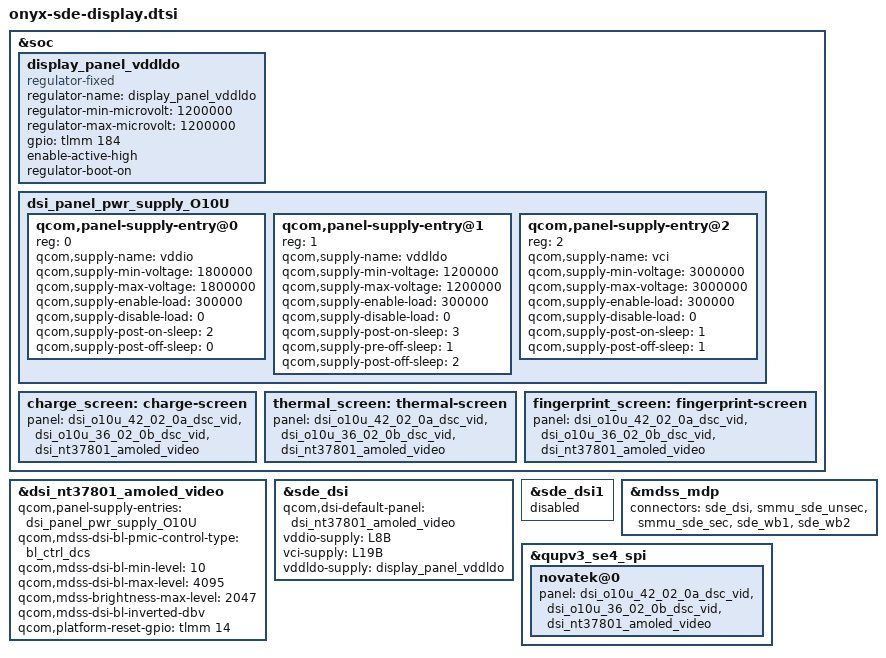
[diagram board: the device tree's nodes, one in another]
#include "tuna-sde-display.dtsi"
#include "dsi-panel-o10u-42-02-0a-dsc-vid.dtsi"
#include "dsi-panel-o10u-36-02-0b-dsc-vid.dtsi"

&soc {
        display_panel_vddldo: display_panel_vddldo {
                compatible = "regulator-fixed";
                regulator-name = "display_panel_vddldo";
                regulator-min-microvolt = <1200000>;
                regulator-max-microvolt = <1200000>;
                gpio = <&tlmm 184 0>;
                enable-active-high;
                regulator-boot-on;
        };

        dsi_panel_pwr_supply_O10U: dsi_panel_pwr_supply_O10U {
                qcom,panel-supply-entry@0 {
                        reg = <0>;
                        qcom,supply-name = "vddio";
                        qcom,supply-min-voltage = <1800000>;
                        qcom,supply-max-voltage = <1800000>;
                        qcom,supply-enable-load = <300000>;
                        qcom,supply-disable-load = <0>;
                        qcom,supply-post-on-sleep = <2>;
                        qcom,supply-post-off-sleep = <0>;
                };
                qcom,panel-supply-entry@1 {
                        reg = <1>;
                        qcom,supply-name = "vddldo";
                        qcom,supply-min-voltage = <1200000>;
                        qcom,supply-max-voltage = <1200000>;
                        qcom,supply-enable-load = <300000>;
                        qcom,supply-disable-load = <0>;
                        qcom,supply-post-on-sleep = <3>;
                        qcom,supply-pre-off-sleep = <1>;
                        qcom,supply-post-off-sleep = <2>;

                };
                qcom,panel-supply-entry@2 {
                        reg = <2>;
                        qcom,supply-name = "vci";
                        qcom,supply-min-voltage = <3000000>;
                        qcom,supply-max-voltage = <3000000>;
                        qcom,supply-enable-load = <300000>;
                        qcom,supply-disable-load = <0>;
                        qcom,supply-post-on-sleep = <1>;
                        qcom,supply-post-off-sleep = <1>;
                };
        };
};


&dsi_nt37801_amoled_video {
        qcom,panel-supply-entries = <&dsi_panel_pwr_supply_O10U>;
        qcom,mdss-dsi-bl-pmic-control-type = "bl_ctrl_dcs";
        qcom,mdss-dsi-bl-min-level = <10>;
        qcom,mdss-dsi-bl-max-level = <4095>;
        qcom,mdss-brightness-max-level = <2047>;
        qcom,mdss-dsi-bl-inverted-dbv;
        qcom,platform-reset-gpio = <&tlmm 14 0>;
};

&sde_dsi {
	qcom,dsi-default-panel = <&dsi_nt37801_amoled_video>;
	vddio-supply = <&L8B>;
	vci-supply = <&L19B>;
	vddldo-supply = <&display_panel_vddldo>;
};

&sde_dsi1 {
	status = "disabled";
};

&mdss_mdp {
	connectors = <&sde_dsi &smmu_sde_unsec &smmu_sde_sec &sde_wb1 &sde_wb2>;
};

&qupv3_se4_spi {
	novatek@0 {
		panel = <&dsi_o10u_42_02_0a_dsc_vid
		    &dsi_o10u_36_02_0b_dsc_vid
			&dsi_nt37801_amoled_video>;
	};
};

&soc {
	charge_screen: charge-screen {
		panel  = <&dsi_o10u_42_02_0a_dsc_vid
		    &dsi_o10u_36_02_0b_dsc_vid
			&dsi_nt37801_amoled_video>;
	};
};

&soc {
	thermal_screen: thermal-screen {
		panel = <&dsi_o10u_42_02_0a_dsc_vid
		    &dsi_o10u_36_02_0b_dsc_vid
			&dsi_nt37801_amoled_video>;
	};
	fingerprint_screen: fingerprint-screen {
		panel = <&dsi_o10u_42_02_0a_dsc_vid
		    &dsi_o10u_36_02_0b_dsc_vid
			&dsi_nt37801_amoled_video>;
	};
};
